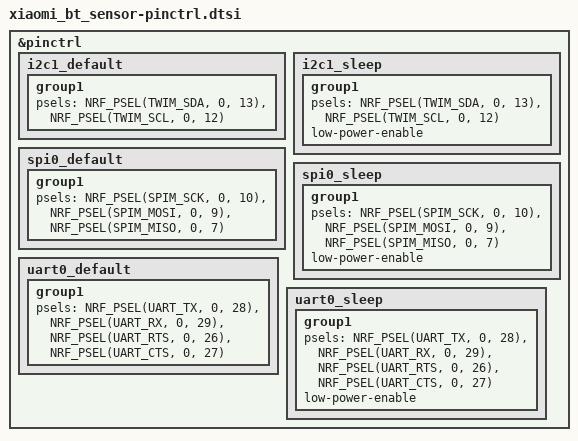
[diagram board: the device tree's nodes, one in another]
/*
 * Copyright (c) 2022 Nordic Semiconductor
 * SPDX-License-Identifier: Apache-2.0
 */

&pinctrl {
	i2c1_default: i2c1_default {
		group1 {
			psels = <NRF_PSEL(TWIM_SDA, 0, 13)>,
					<NRF_PSEL(TWIM_SCL, 0, 12)>;
		};
	};

	i2c1_sleep: i2c1_sleep {
		group1 {
			psels = <NRF_PSEL(TWIM_SDA, 0, 13)>,
					<NRF_PSEL(TWIM_SCL, 0, 12)>;
			low-power-enable;
		};
	};

	spi0_default: spi0_default {
		group1 {
			psels = <NRF_PSEL(SPIM_SCK, 0, 10)>,
			        <NRF_PSEL(SPIM_MOSI, 0, 9)>,
			        <NRF_PSEL(SPIM_MISO, 0, 7)>;
		};
	};

	spi0_sleep: spi0_sleep {
		group1 {
			psels = <NRF_PSEL(SPIM_SCK, 0, 10)>,
			        <NRF_PSEL(SPIM_MOSI, 0, 9)>,
			        <NRF_PSEL(SPIM_MISO, 0, 7)>;
			low-power-enable;
		};
	};

	uart0_default: uart0_default {
		group1 {
			psels = <NRF_PSEL(UART_TX, 0, 28)>,
			        <NRF_PSEL(UART_RX, 0, 29)>,
			        <NRF_PSEL(UART_RTS, 0, 26)>,
			        <NRF_PSEL(UART_CTS, 0, 27)>;
		};
	};

	uart0_sleep: uart0_sleep {
		group1 {
			psels = <NRF_PSEL(UART_TX, 0, 28)>,
			        <NRF_PSEL(UART_RX, 0, 29)>,
			        <NRF_PSEL(UART_RTS, 0, 26)>,
			        <NRF_PSEL(UART_CTS, 0, 27)>;
			low-power-enable;
		};
	};

};
